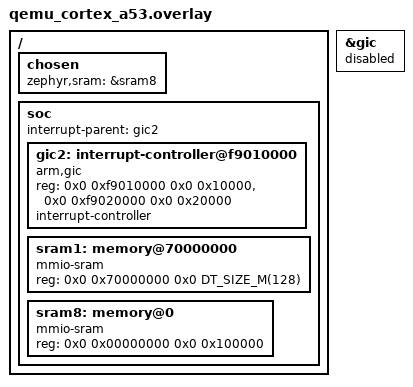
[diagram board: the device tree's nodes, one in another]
/ {
    chosen {
		zephyr,sram = &sram8;
	};

    /* jailhouse config for zephyr assing memory area into 0x7000000 */
    soc {

		interrupt-parent = <&gic2>;

		gic2: interrupt-controller@f9010000 {
			compatible = "arm,gic";
			#interrupt-cells = <4>;
			reg = <0x0 0xf9010000 0x0 0x10000>,
			      <0x0 0xf9020000 0x0 0x20000>;
			interrupt-controller;
			status = "okay";
		};

		sram1: memory@70000000 {
			compatible = "mmio-sram";
			reg = <0x0 0x70000000 0x0 DT_SIZE_M(128)>;
		};

		sram8: memory@0 {
			compatible = "mmio-sram";
			reg = <0x0 0x00000000 0x0 0x100000>;
		};
	};
};

&gic {
	status = "disabled";
};
